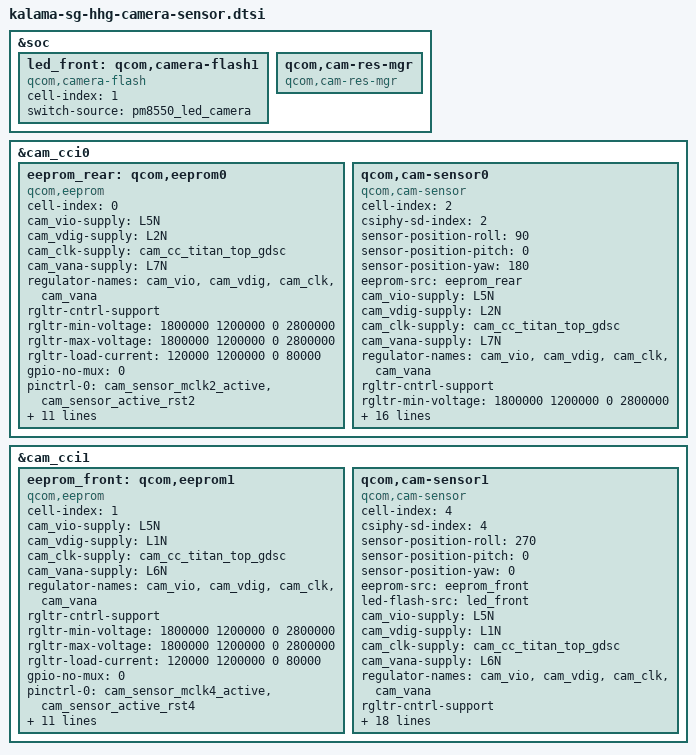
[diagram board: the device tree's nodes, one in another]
#include <dt-bindings/msm-camera.h>

&soc {
	led_front: qcom,camera-flash1 {
		cell-index = <1>;
		compatible = "qcom,camera-flash";
		switch-source = <&pm8550_led_camera>;
		status = "ok";
	};

	qcom,cam-res-mgr {
		compatible = "qcom,cam-res-mgr";
		status = "ok";
	};
};

&cam_cci0 {
	eeprom_rear: qcom,eeprom0 {
		cell-index = <0>;
		compatible = "qcom,eeprom";
		cam_vio-supply = <&L5N>;
		cam_vdig-supply = <&L2N>;
		cam_clk-supply = <&cam_cc_titan_top_gdsc>;
		cam_vana-supply = <&L7N>;
		regulator-names = "cam_vio", "cam_vdig", "cam_clk",
			"cam_vana";
		rgltr-cntrl-support;
		rgltr-min-voltage = <1800000 1200000 0 2800000>;
		rgltr-max-voltage = <1800000 1200000 0 2800000>;
		rgltr-load-current = <120000 1200000 0 80000>;
		gpio-no-mux = <0>;
		pinctrl-names = "cam_default", "cam_suspend";
		pinctrl-0 = <&cam_sensor_mclk2_active
				 &cam_sensor_active_rst2>;
		pinctrl-1 = <&cam_sensor_mclk2_suspend
				 &cam_sensor_suspend_rst2>;
		gpios = <&tlmm 102 0>,
			<&tlmm 118 0>;
		gpio-reset = <1>;
		gpio-req-tbl-num = <0 1>;
		gpio-req-tbl-flags = <1 0>;
		gpio-req-tbl-label = "CAMIF_MCLK2",
					"CAM_RESET2";
		cci-master = <CCI_MASTER_1>;
		clocks = <&camcc CAM_CC_MCLK2_CLK>;
		clock-names = "cam_clk";
		clock-cntl-level = "nominal";
		clock-rates = <24000000>;
		status = "ok";
	};

	qcom,cam-sensor0 {
		cell-index = <2>;
		compatible = "qcom,cam-sensor";
		csiphy-sd-index = <2>;
		sensor-position-roll = <90>;
		sensor-position-pitch = <0>;
		sensor-position-yaw = <180>;
		eeprom-src = <&eeprom_rear>;
		cam_vio-supply = <&L5N>;
		cam_vdig-supply = <&L2N>;
		cam_clk-supply = <&cam_cc_titan_top_gdsc>;
		cam_vana-supply = <&L7N>;
		regulator-names = "cam_vio", "cam_vdig", "cam_clk",
			"cam_vana";
		rgltr-cntrl-support;
		rgltr-min-voltage = <1800000 1200000 0 2800000>;
		rgltr-max-voltage = <1800000 1200000 0 2800000>;
		rgltr-load-current = <120000 1200000 0 80000>;
		gpio-no-mux = <0>;
		pinctrl-names = "cam_default", "cam_suspend";
		pinctrl-0 = <&cam_sensor_mclk2_active
				 &cam_sensor_active_rst2>;
		pinctrl-1 = <&cam_sensor_mclk2_suspend
				 &cam_sensor_suspend_rst2>;
		gpios = <&tlmm 102 0>,
			<&tlmm 118 0>;
		gpio-reset = <1>;
		gpio-req-tbl-num = <0 1>;
		gpio-req-tbl-flags = <1 0>;
		gpio-req-tbl-label = "CAMIF_MCLK2",
					"CAM_RESET2";
		cci-master = <CCI_MASTER_1>;
		clocks = <&camcc CAM_CC_MCLK2_CLK>;
		clock-names = "cam_clk";
		clock-cntl-level = "nominal";
		clock-rates = <24000000>;
		status = "ok";
	};
};

&cam_cci1 {
	eeprom_front: qcom,eeprom1 {
		cell-index = <1>;
		compatible = "qcom,eeprom";
		cam_vio-supply = <&L5N>;
		cam_vdig-supply = <&L1N>;
		cam_clk-supply = <&cam_cc_titan_top_gdsc>;
		cam_vana-supply = <&L6N>;
		regulator-names = "cam_vio", "cam_vdig", "cam_clk",
				"cam_vana";
		rgltr-cntrl-support;
		rgltr-min-voltage = <1800000 1200000 0 2800000>;
		rgltr-max-voltage = <1800000 1200000 0 2800000>;
		rgltr-load-current = <120000 1200000 0 80000>;
		gpio-no-mux = <0>;
		pinctrl-names = "cam_default", "cam_suspend";
		pinctrl-0 = <&cam_sensor_mclk4_active
				&cam_sensor_active_rst4>;
		pinctrl-1 = <&cam_sensor_mclk4_suspend
				&cam_sensor_suspend_rst4>;
		gpios = <&tlmm 104 0>,
				<&tlmm 120 0>;
		gpio-reset = <1>;
		gpio-req-tbl-num = <0 1>;
		gpio-req-tbl-flags = <1 0>;
		gpio-req-tbl-label = "CAMIF_MCLK4",
					"CAM_RESET4";
		cci-master = <CCI_MASTER_1>;
		clocks = <&camcc CAM_CC_MCLK4_CLK>;
		clock-names = "cam_clk";
		clock-cntl-level = "nominal";
		clock-rates = <24000000>;
		status = "ok";
	};

	qcom,cam-sensor1 {
		cell-index = <4>;
		compatible = "qcom,cam-sensor";
		csiphy-sd-index = <4>;
		sensor-position-roll = <270>;
		sensor-position-pitch = <0>;
		sensor-position-yaw = <0>;
		eeprom-src = <&eeprom_front>;
		led-flash-src = <&led_front>;
		cam_vio-supply = <&L5N>;
		cam_vdig-supply = <&L1N>;
		cam_clk-supply = <&cam_cc_titan_top_gdsc>;
		cam_vana-supply = <&L6N>;
		regulator-names = "cam_vio", "cam_vdig","cam_clk", "cam_vana";
		rgltr-cntrl-support;
		aon-camera-id = <AON_CAM1>;
		rgltr-min-voltage = <1800000 1200000 0 2800000>;
		rgltr-max-voltage = <1800000 1200000 0 2800000>;
		rgltr-load-current = <120000 1200000 0  80000>;
		gpio-no-mux = <0>;
		pinctrl-names = "cam_default", "cam_suspend";
		pinctrl-0 = <&cam_sensor_mclk4_active
				 &cam_sensor_active_rst4>;
		pinctrl-1 = <&cam_sensor_mclk4_suspend
				 &cam_sensor_suspend_rst4>;
		gpios = <&tlmm 104 0>,
			<&tlmm 120 0>;
		gpio-reset = <1>;
		gpio-req-tbl-num = <0 1>;
		gpio-req-tbl-flags = <1 0>;
		gpio-req-tbl-label = "CAMIF_MCLK4",
					"CAM_RESET4";
		cci-master = <CCI_MASTER_1>;
		clocks = <&camcc CAM_CC_MCLK4_CLK>;
		clock-names = "cam_clk";
		clock-cntl-level = "nominal";
		clock-rates = <24000000>;
		status = "ok";
	};
};

